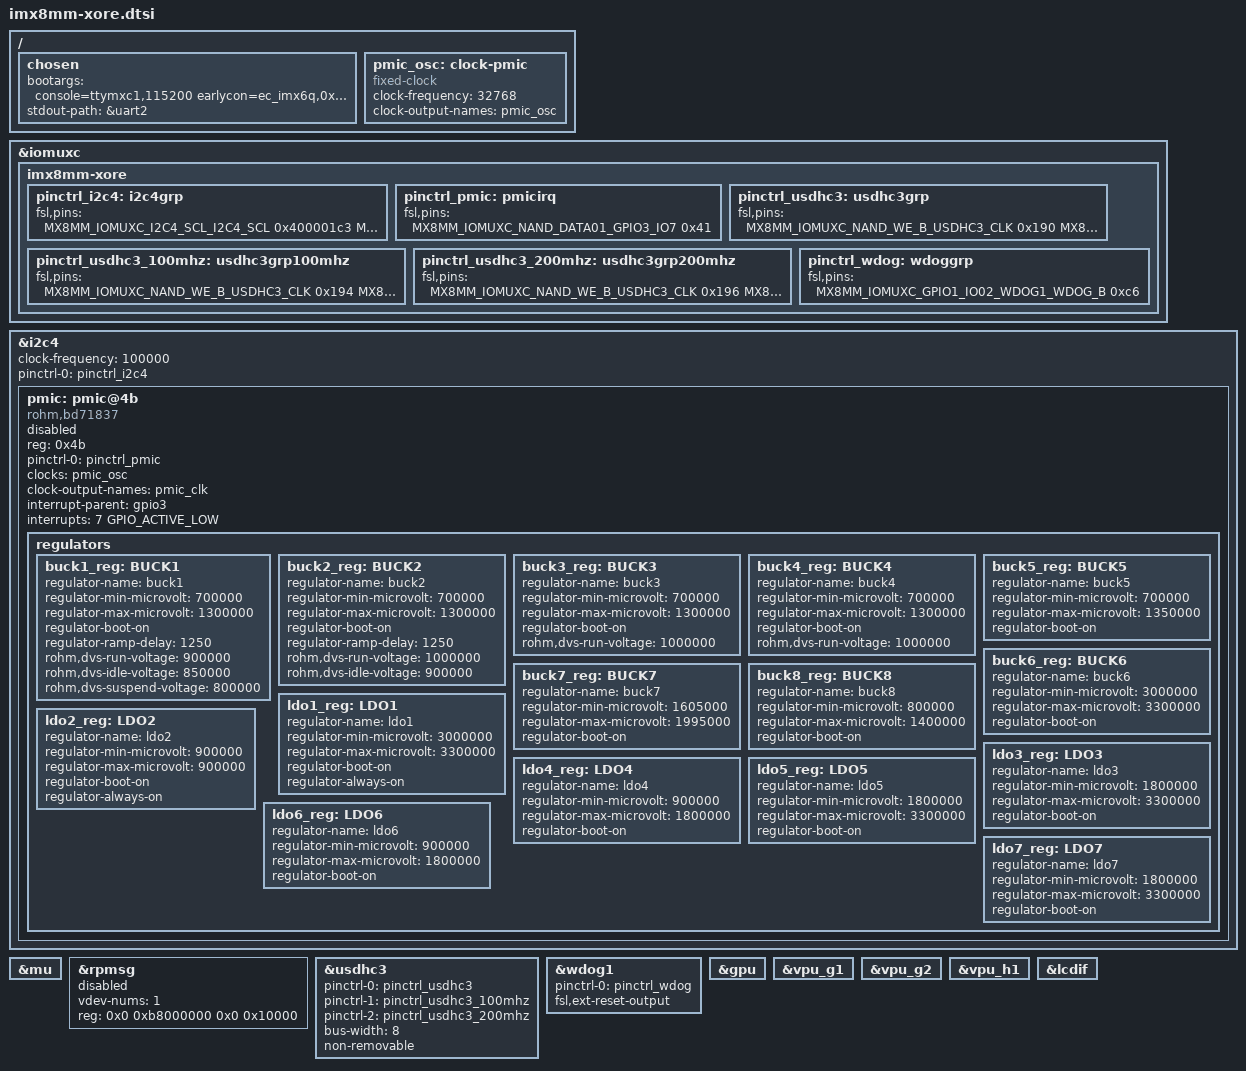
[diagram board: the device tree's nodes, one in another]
/*
 * Copyright 2018 TechNexion Ltd.
 * Copyright 2018 NXP
 *
 * Author: Richard Hu <richard.hu@technexion.com>
 *         Ray Chang <ray.chang@technexion.com>
 *         Andy Lin <andy.lin@technexion.com>
 *
 * This program is free software; you can redistribute it and/or
 * modify it under the terms of the GNU General Public License
 * as published by the Free Software Foundation; either version 2
 * of the License, or (at your option) any later version.
 *
 * This program is distributed in the hope that it will be useful,
 * but WITHOUT ANY WARRANTY; without even the implied warranty of
 * MERCHANTABILITY or FITNESS FOR A PARTICULAR PURPOSE.  See the
 * GNU General Public License for more details.
 */

/dts-v1/;

#include "imx8mm.dtsi"

/ {
	chosen {
		bootargs = "console=ttymxc1,115200 earlycon=ec_imx6q,0x30890000,115200";
		stdout-path = &uart2;
	};

	pmic_osc: clock-pmic {
		compatible = "fixed-clock";
		#clock-cells = <0>;
		clock-frequency = <32768>;
		clock-output-names = "pmic_osc";
	};
};

&iomuxc {
	pinctrl-names = "default";

	imx8mm-xore {
		pinctrl_i2c4: i2c4grp {
			fsl,pins = <
				MX8MM_IOMUXC_I2C4_SCL_I2C4_SCL		0x400001c3
				MX8MM_IOMUXC_I2C4_SDA_I2C4_SDA		0x400001c3
			>;
		};

		pinctrl_pmic: pmicirq {
			fsl,pins = <
				MX8MM_IOMUXC_NAND_DATA01_GPIO3_IO7	0x41
			>;
		};

		pinctrl_usdhc3: usdhc3grp {
			fsl,pins = <
				MX8MM_IOMUXC_NAND_WE_B_USDHC3_CLK	0x190
				MX8MM_IOMUXC_NAND_WP_B_USDHC3_CMD	0x1d0
				MX8MM_IOMUXC_NAND_DATA04_USDHC3_DATA0	0x1d0
				MX8MM_IOMUXC_NAND_DATA05_USDHC3_DATA1	0x1d0
				MX8MM_IOMUXC_NAND_DATA06_USDHC3_DATA2	0x1d0
				MX8MM_IOMUXC_NAND_DATA07_USDHC3_DATA3	0x1d0
				MX8MM_IOMUXC_NAND_RE_B_USDHC3_DATA4	0x1d0
				MX8MM_IOMUXC_NAND_CE2_B_USDHC3_DATA5	0x1d0
				MX8MM_IOMUXC_NAND_CE3_B_USDHC3_DATA6	0x1d0
				MX8MM_IOMUXC_NAND_CLE_USDHC3_DATA7	0x1d0
				MX8MM_IOMUXC_NAND_CE1_B_USDHC3_STROBE 	0x190
			>;
		};

		pinctrl_usdhc3_100mhz: usdhc3grp100mhz {
			fsl,pins = <
				MX8MM_IOMUXC_NAND_WE_B_USDHC3_CLK	0x194
				MX8MM_IOMUXC_NAND_WP_B_USDHC3_CMD	0x1d4
				MX8MM_IOMUXC_NAND_DATA04_USDHC3_DATA0	0x1d4
				MX8MM_IOMUXC_NAND_DATA05_USDHC3_DATA1	0x1d4
				MX8MM_IOMUXC_NAND_DATA06_USDHC3_DATA2	0x1d4
				MX8MM_IOMUXC_NAND_DATA07_USDHC3_DATA3	0x1d4
				MX8MM_IOMUXC_NAND_RE_B_USDHC3_DATA4	0x1d4
				MX8MM_IOMUXC_NAND_CE2_B_USDHC3_DATA5	0x1d4
				MX8MM_IOMUXC_NAND_CE3_B_USDHC3_DATA6	0x1d4
				MX8MM_IOMUXC_NAND_CLE_USDHC3_DATA7	0x1d4
				MX8MM_IOMUXC_NAND_CE1_B_USDHC3_STROBE 	0x194
			>;
		};

		pinctrl_usdhc3_200mhz: usdhc3grp200mhz {
			fsl,pins = <
				MX8MM_IOMUXC_NAND_WE_B_USDHC3_CLK	0x196
				MX8MM_IOMUXC_NAND_WP_B_USDHC3_CMD	0x1d6
				MX8MM_IOMUXC_NAND_DATA04_USDHC3_DATA0	0x1d6
				MX8MM_IOMUXC_NAND_DATA05_USDHC3_DATA1	0x1d6
				MX8MM_IOMUXC_NAND_DATA06_USDHC3_DATA2	0x1d6
				MX8MM_IOMUXC_NAND_DATA07_USDHC3_DATA3	0x1d6
				MX8MM_IOMUXC_NAND_RE_B_USDHC3_DATA4	0x1d6
				MX8MM_IOMUXC_NAND_CE2_B_USDHC3_DATA5	0x1d6
				MX8MM_IOMUXC_NAND_CE3_B_USDHC3_DATA6	0x1d6
				MX8MM_IOMUXC_NAND_CLE_USDHC3_DATA7	0x1d6
				MX8MM_IOMUXC_NAND_CE1_B_USDHC3_STROBE 	0x196
			>;
		};

		pinctrl_wdog: wdoggrp {
			fsl,pins = <
				MX8MM_IOMUXC_GPIO1_IO02_WDOG1_WDOG_B	0xc6
			>;
		};
	};
};

&i2c4 {
	clock-frequency = <100000>;
	pinctrl-names = "default";
	pinctrl-0 = <&pinctrl_i2c4>;
	status = "okay";

	pmic: pmic@4b {
		reg = <0x4b>;
		compatible = "rohm,bd71837";
		pinctrl-names = "default";
		pinctrl-0 = <&pinctrl_pmic>;
		clocks = <&pmic_osc>;
		clock-names = "osc";
		clock-output-names = "pmic_clk";
		interrupt-parent = <&gpio3>;
		interrupts = <7 GPIO_ACTIVE_LOW>;
		interrupt-names = "irq";
		status = "disabled";

		regulators {
			buck1_reg: BUCK1 {
				regulator-name = "buck1";
				regulator-min-microvolt = <700000>;
				regulator-max-microvolt = <1300000>;
				regulator-boot-on;
				regulator-ramp-delay = <1250>;
				rohm,dvs-run-voltage = <900000>;
				rohm,dvs-idle-voltage = <850000>;
				rohm,dvs-suspend-voltage = <800000>;
			};

			buck2_reg: BUCK2 {
				regulator-name = "buck2";
				regulator-min-microvolt = <700000>;
				regulator-max-microvolt = <1300000>;
				regulator-boot-on;
				regulator-ramp-delay = <1250>;
				rohm,dvs-run-voltage = <1000000>;
				rohm,dvs-idle-voltage = <900000>;
			};

			buck3_reg: BUCK3 {
				regulator-name = "buck3";
				regulator-min-microvolt = <700000>;
				regulator-max-microvolt = <1300000>;
				regulator-boot-on;
				rohm,dvs-run-voltage = <1000000>;
			};

			buck4_reg: BUCK4 {
				regulator-name = "buck4";
				regulator-min-microvolt = <700000>;
				regulator-max-microvolt = <1300000>;
				regulator-boot-on;
				rohm,dvs-run-voltage = <1000000>;
			};

			buck5_reg: BUCK5 {
				regulator-name = "buck5";
				regulator-min-microvolt = <700000>;
				regulator-max-microvolt = <1350000>;
				regulator-boot-on;
			};

			buck6_reg: BUCK6 {
				regulator-name = "buck6";
				regulator-min-microvolt = <3000000>;
				regulator-max-microvolt = <3300000>;
				regulator-boot-on;
			};

			buck7_reg: BUCK7 {
				regulator-name = "buck7";
				regulator-min-microvolt = <1605000>;
				regulator-max-microvolt = <1995000>;
				regulator-boot-on;
			};

			buck8_reg: BUCK8 {
				regulator-name = "buck8";
				regulator-min-microvolt = <800000>;
				regulator-max-microvolt = <1400000>;
				regulator-boot-on;
			};

			ldo1_reg: LDO1 {
				regulator-name = "ldo1";
				regulator-min-microvolt = <3000000>;
				regulator-max-microvolt = <3300000>;
				regulator-boot-on;
				regulator-always-on;
			};

			ldo2_reg: LDO2 {
				regulator-name = "ldo2";
				regulator-min-microvolt = <900000>;
				regulator-max-microvolt = <900000>;
				regulator-boot-on;
				regulator-always-on;
			};

			ldo3_reg: LDO3 {
				regulator-name = "ldo3";
				regulator-min-microvolt = <1800000>;
				regulator-max-microvolt = <3300000>;
				regulator-boot-on;
			};

			ldo4_reg: LDO4 {
				regulator-name = "ldo4";
				regulator-min-microvolt = <900000>;
				regulator-max-microvolt = <1800000>;
				regulator-boot-on;
			};

			ldo5_reg: LDO5 {
				regulator-name = "ldo5";
				regulator-min-microvolt = <1800000>;
				regulator-max-microvolt = <3300000>;
				regulator-boot-on;
			};

			ldo6_reg: LDO6 {
				regulator-name = "ldo6";
				regulator-min-microvolt = <900000>;
				regulator-max-microvolt = <1800000>;
				regulator-boot-on;
			};

			ldo7_reg: LDO7 {
				regulator-name = "ldo7";
				regulator-min-microvolt = <1800000>;
				regulator-max-microvolt = <3300000>;
				regulator-boot-on;
			};
		};
	};
};

&mu {
	status = "okay";
};

&rpmsg {
	/*
	 * 64K for one rpmsg instance:
	 * --0xb8000000~0xb800ffff: pingpong
	 */
	vdev-nums = <1>;
	reg = <0x0 0xb8000000 0x0 0x10000>;
	status = "disabled";
};

/* eMMC on SOM */
&usdhc3 {
	pinctrl-names = "default", "state_100mhz", "state_200mhz";
	pinctrl-0 = <&pinctrl_usdhc3>;
	pinctrl-1 = <&pinctrl_usdhc3_100mhz>;
	pinctrl-2 = <&pinctrl_usdhc3_200mhz>;
	bus-width = <8>;
	non-removable;
	status = "okay";
};

&wdog1 {
	pinctrl-names = "default";
	pinctrl-0 = <&pinctrl_wdog>;
	fsl,ext-reset-output;
	status = "okay";
};

&gpu {
	status = "okay";
};

&vpu_g1 {
	status = "okay";
};

&vpu_g2 {
	status = "okay";
};

&vpu_h1 {
	status = "okay";
};

&lcdif {
	status = "okay";
};
